VERSION ""

NS_ :

BS_:

BU_: TC162_SN_00001234

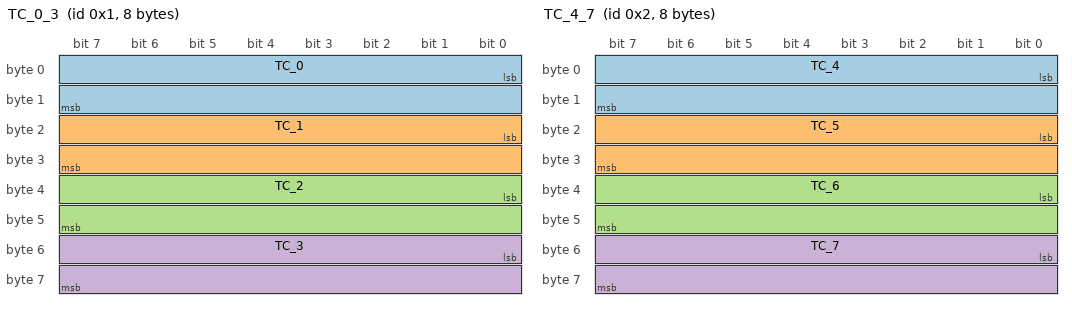
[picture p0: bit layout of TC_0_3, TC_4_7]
BO_ 1 TC_0_3: 8 TC162_SN_00001234
 SG_ TC_0 : 0|16@1- (0.0625,0) [-200|1250] "deg C" Vector__XXX
 SG_ TC_1 : 16|16@1- (0.0625,0) [-200|1250] "deg C" Vector__XXX
 SG_ TC_2 : 32|16@1- (0.0625,0) [-200|1250] "deg C" Vector__XXX
 SG_ TC_3 : 48|16@1- (0.0625,0) [-200|1250] "deg C" Vector__XXX

BO_ 2 TC_4_7: 8 TC162_SN_00001234
 SG_ TC_4 : 0|16@1- (0.0625,0) [-200|1250] "deg C" Vector__XXX
 SG_ TC_5 : 16|16@1- (0.0625,0) [-200|1250] "deg C" Vector__XXX
 SG_ TC_6 : 32|16@1- (0.0625,0) [-200|1250] "deg C" Vector__XXX
 SG_ TC_7 : 48|16@1- (0.0625,0) [-200|1250] "deg C" Vector__XXX

BO_ 256 OutputAverage: 8 Vector__XXX
 SG_ Average : 0|32@1- (0.001,0) [0|0] "" Vector__XXX

CM_ BO_ 1 "Rate: 100 ms, Use: 1, TC Units: 0";
CM_ SG_ 1 TC_0 "TC Type: 0";
CM_ SG_ 1 TC_1 "TC Type: 0";
CM_ SG_ 1 TC_2 "TC Type: 0";
CM_ SG_ 1 TC_3 "TC Type: 0";
CM_ BO_ 2 "Rate: 100 ms, Use: 1, TC Units: 0";
CM_ SG_ 2 TC_4 "TC Type: 0";
CM_ SG_ 2 TC_5 "TC Type: 0";
CM_ SG_ 2 TC_6 "TC Type: 0";
CM_ SG_ 2 TC_7 "TC Type: 0";
